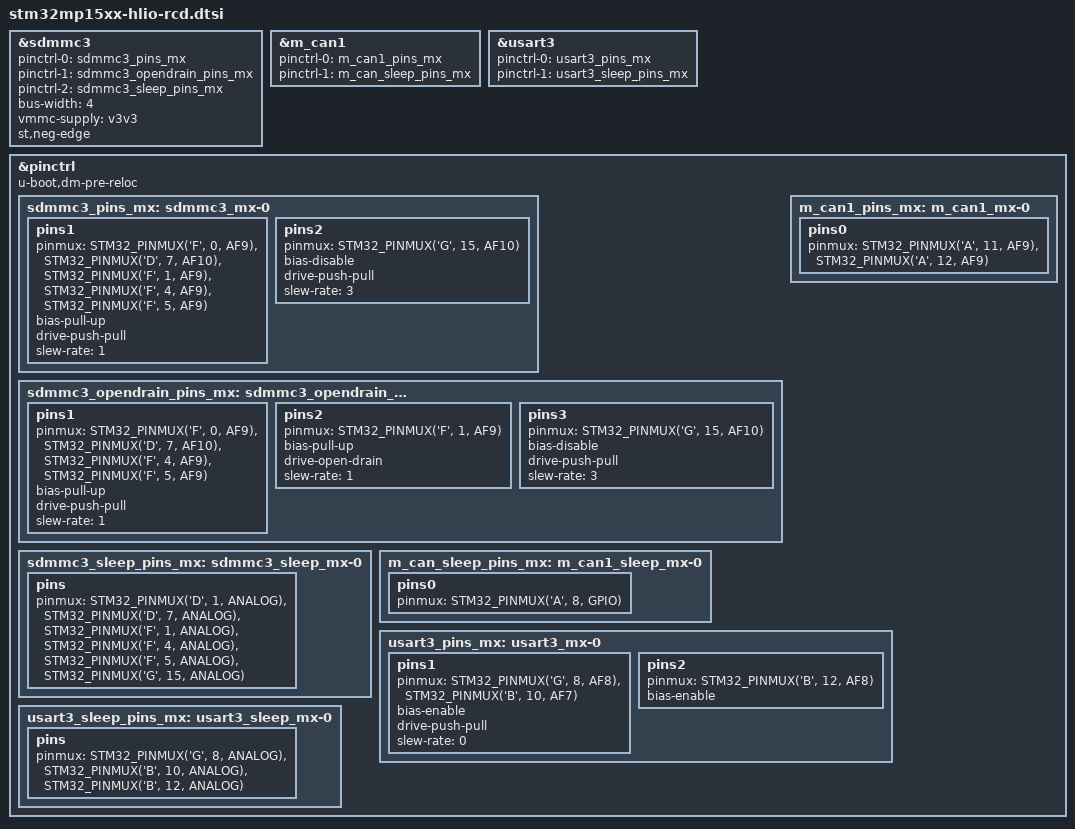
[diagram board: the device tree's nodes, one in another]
// SPDX-License-Identifier: (GPL-2.0+ OR BSD-3-Clause)
/*
 * Copyright (C) Helios Technologies 2021 - All Rights Reserved
 * Author: Stephen Livingston (stephen.livingston@hlioengineering.com)
 * stm32mp157c-dk2-user.dtsi - Additions to STMicroelectronics supplied stm32mp157c-dk2.dts
 * 
 */

/* ESP32 Module SDIO */
&sdmmc3 {
//		arm,primecell-periphid = <0x10153180>;
		pinctrl-names = "default", "opendrain", "sleep";
		pinctrl-0 = <&sdmmc3_pins_mx>;
		pinctrl-1 = <&sdmmc3_opendrain_pins_mx>;
		pinctrl-2 = <&sdmmc3_sleep_pins_mx>;
		bus-width = <4>;
		vmmc-supply = <&v3v3>;
//		max-frequency = <400000>;
		st,neg-edge;
//		non-removable;
//		cap-sdio-irq;
//		interrupts-extended = <&exti ?? IRQ_TYPE_LEVEL_HIGH>;
		status = "okay";

    /* USER CODE BEGIN sdmmc3 */
    /* USER CODE END sdmmc3 */
};

/* FDCAN configure */
&m_can1 {
	pinctrl-names = "default", "sleep";
	pinctrl-0 = <&m_can1_pins_mx>;
	pinctrl-1 = <&m_can_sleep_pins_mx>;
	status = "okay";
};

/* FDCAN configure */
// &m_can2 {
// 	pinctrl-names = "default", "sleep";
// 	pinctrl-0 = <&m_can2_pins_mx>;
// 	pinctrl-1 = <&m_can_sleep_pins_mx>;
// 	status = "okay";
// };

&usart3{
	pinctrl-names = "default", "sleep";
	pinctrl-0 = <&usart3_pins_mx>;
	pinctrl-1 = <&usart3_sleep_pins_mx>;
	status = "okay";

	/* USER CODE BEGIN usart3 */
	/* USER CODE END usart3 */
};

&pinctrl {
	u-boot,dm-pre-reloc;

	sdmmc3_pins_mx: sdmmc3_mx-0 {
		pins1 {
			pinmux = <STM32_PINMUX('F', 0, AF9)>, /* SDMMC3_D0 */
					 <STM32_PINMUX('D', 7, AF10)>, /* SDMMC3_D3 */
					 <STM32_PINMUX('F', 1, AF9)>, /* SDMMC3_CMD */
					 <STM32_PINMUX('F', 4, AF9)>, /* SDMMC3_D1 */
					 <STM32_PINMUX('F', 5, AF9)>; /* SDMMC3_D2 */
			bias-pull-up;
			drive-push-pull;
			slew-rate = <1>;
		};
		pins2 {
			pinmux = <STM32_PINMUX('G', 15, AF10)>; /* SDMMC3_CK */
			bias-disable;
			drive-push-pull;
			slew-rate = <3>;
		};
	};

	sdmmc3_opendrain_pins_mx: sdmmc3_opendrain_mx-0 {
		pins1 {
			pinmux = <STM32_PINMUX('F', 0, AF9)>, /* SDMMC3_D0 */
					 <STM32_PINMUX('D', 7, AF10)>, /* SDMMC3_D3 */
					 <STM32_PINMUX('F', 4, AF9)>, /* SDMMC3_D1 */
					 <STM32_PINMUX('F', 5, AF9)>; /* SDMMC3_D2 */
			bias-pull-up;
			drive-push-pull;
			slew-rate = <1>;
		};
		pins2 {
			pinmux = <STM32_PINMUX('F', 1, AF9)>; /* SDMMC3_CMD */
			bias-pull-up;
			drive-open-drain;
			slew-rate = <1>;
		};
		pins3 {
			pinmux = <STM32_PINMUX('G', 15, AF10)>; /* SDMMC3_CK */
			bias-disable;
			drive-push-pull;
			slew-rate = <3>;
		};
	};

	sdmmc3_sleep_pins_mx: sdmmc3_sleep_mx-0 {
		pins {
			pinmux = <STM32_PINMUX('D', 1, ANALOG)>, /* SDMMC3_D0 */
					 <STM32_PINMUX('D', 7, ANALOG)>, /* SDMMC3_D3 */
					 <STM32_PINMUX('F', 1, ANALOG)>, /* SDMMC3_CMD */
					 <STM32_PINMUX('F', 4, ANALOG)>, /* SDMMC3_D1 */
					 <STM32_PINMUX('F', 5, ANALOG)>, /* SDMMC3_D2 */
					 <STM32_PINMUX('G', 15, ANALOG)>; /* SDMMC3_CK */
		};
	};

	m_can1_pins_mx: m_can1_mx-0 {
		pins0 {
			pinmux = <STM32_PINMUX('A', 11, AF9)>, /* CAN1_RX */
					 <STM32_PINMUX('A', 12, AF9)>; /* CAN1_TX */
		};
	};

	// m_can2_pins_mx: m_can1_mx-0 {
	// 	pins0 {
	// 		pinmux = <STM32_PINMUX('B', 5, AF9)>,  /* CAN1_RX */
	// 				 <STM32_PINMUX('B', 13, AF9)>; /* CAN1_TX */
	// 	};
	// };

	m_can_sleep_pins_mx: m_can1_sleep_mx-0 {
		pins0 {
			pinmux = <STM32_PINMUX('A', 8, GPIO)>; /* CAN1_SLEEP */
		};
	};

	usart3_pins_mx: usart3_mx-0 {
		pins1 {
			pinmux = <STM32_PINMUX('G', 8, AF8)>, /* USART3_DE */
					 <STM32_PINMUX('B', 10, AF7)>; /* USART3_TX */
			bias-enable;
			drive-push-pull;
			slew-rate = <0>;
		};
		pins2 {
			pinmux = <STM32_PINMUX('B', 12, AF8)>; /* USART3_RX */
			bias-enable;
		};
	};

	usart3_sleep_pins_mx: usart3_sleep_mx-0 {
		pins {
			pinmux = <STM32_PINMUX('G', 8, ANALOG)>, /* USART3_DE */
					 <STM32_PINMUX('B', 10, ANALOG)>, /* USART3_TX */
					 <STM32_PINMUX('B', 12, ANALOG)>; /* USART3_RX */
		};
	};

};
